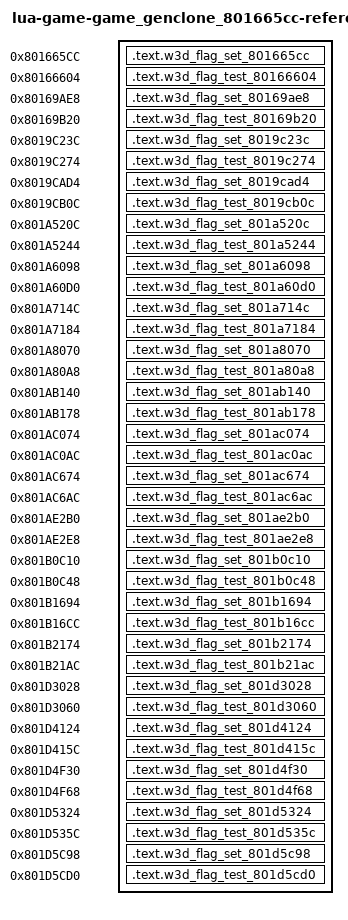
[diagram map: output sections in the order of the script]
/* Generated reference-only placements. All bodies are source-built. */
OUTPUT_FORMAT("elf32-powerpc")
OUTPUT_ARCH(powerpc)
ENTRY(w3d_flag_set_801665cc)
_SDA_BASE_ = 0x804b2540;
_SDA2_BASE_ = 0x804c2540;
SECTIONS {
  .text.w3d_flag_set_801665cc 0x801665cc : { *(.text.w3d_flag_set_801665cc) }
  .text.w3d_flag_test_80166604 0x80166604 : { *(.text.w3d_flag_test_80166604) }
  .text.w3d_flag_set_80169ae8 0x80169ae8 : { *(.text.w3d_flag_set_80169ae8) }
  .text.w3d_flag_test_80169b20 0x80169b20 : { *(.text.w3d_flag_test_80169b20) }
  .text.w3d_flag_set_8019c23c 0x8019c23c : { *(.text.w3d_flag_set_8019c23c) }
  .text.w3d_flag_test_8019c274 0x8019c274 : { *(.text.w3d_flag_test_8019c274) }
  .text.w3d_flag_set_8019cad4 0x8019cad4 : { *(.text.w3d_flag_set_8019cad4) }
  .text.w3d_flag_test_8019cb0c 0x8019cb0c : { *(.text.w3d_flag_test_8019cb0c) }
  .text.w3d_flag_set_801a520c 0x801a520c : { *(.text.w3d_flag_set_801a520c) }
  .text.w3d_flag_test_801a5244 0x801a5244 : { *(.text.w3d_flag_test_801a5244) }
  .text.w3d_flag_set_801a6098 0x801a6098 : { *(.text.w3d_flag_set_801a6098) }
  .text.w3d_flag_test_801a60d0 0x801a60d0 : { *(.text.w3d_flag_test_801a60d0) }
  .text.w3d_flag_set_801a714c 0x801a714c : { *(.text.w3d_flag_set_801a714c) }
  .text.w3d_flag_test_801a7184 0x801a7184 : { *(.text.w3d_flag_test_801a7184) }
  .text.w3d_flag_set_801a8070 0x801a8070 : { *(.text.w3d_flag_set_801a8070) }
  .text.w3d_flag_test_801a80a8 0x801a80a8 : { *(.text.w3d_flag_test_801a80a8) }
  .text.w3d_flag_set_801ab140 0x801ab140 : { *(.text.w3d_flag_set_801ab140) }
  .text.w3d_flag_test_801ab178 0x801ab178 : { *(.text.w3d_flag_test_801ab178) }
  .text.w3d_flag_set_801ac074 0x801ac074 : { *(.text.w3d_flag_set_801ac074) }
  .text.w3d_flag_test_801ac0ac 0x801ac0ac : { *(.text.w3d_flag_test_801ac0ac) }
  .text.w3d_flag_set_801ac674 0x801ac674 : { *(.text.w3d_flag_set_801ac674) }
  .text.w3d_flag_test_801ac6ac 0x801ac6ac : { *(.text.w3d_flag_test_801ac6ac) }
  .text.w3d_flag_set_801ae2b0 0x801ae2b0 : { *(.text.w3d_flag_set_801ae2b0) }
  .text.w3d_flag_test_801ae2e8 0x801ae2e8 : { *(.text.w3d_flag_test_801ae2e8) }
  .text.w3d_flag_set_801b0c10 0x801b0c10 : { *(.text.w3d_flag_set_801b0c10) }
  .text.w3d_flag_test_801b0c48 0x801b0c48 : { *(.text.w3d_flag_test_801b0c48) }
  .text.w3d_flag_set_801b1694 0x801b1694 : { *(.text.w3d_flag_set_801b1694) }
  .text.w3d_flag_test_801b16cc 0x801b16cc : { *(.text.w3d_flag_test_801b16cc) }
  .text.w3d_flag_set_801b2174 0x801b2174 : { *(.text.w3d_flag_set_801b2174) }
  .text.w3d_flag_test_801b21ac 0x801b21ac : { *(.text.w3d_flag_test_801b21ac) }
  .text.w3d_flag_set_801d3028 0x801d3028 : { *(.text.w3d_flag_set_801d3028) }
  .text.w3d_flag_test_801d3060 0x801d3060 : { *(.text.w3d_flag_test_801d3060) }
  .text.w3d_flag_set_801d4124 0x801d4124 : { *(.text.w3d_flag_set_801d4124) }
  .text.w3d_flag_test_801d415c 0x801d415c : { *(.text.w3d_flag_test_801d415c) }
  .text.w3d_flag_set_801d4f30 0x801d4f30 : { *(.text.w3d_flag_set_801d4f30) }
  .text.w3d_flag_test_801d4f68 0x801d4f68 : { *(.text.w3d_flag_test_801d4f68) }
  .text.w3d_flag_set_801d5324 0x801d5324 : { *(.text.w3d_flag_set_801d5324) }
  .text.w3d_flag_test_801d535c 0x801d535c : { *(.text.w3d_flag_test_801d535c) }
  .text.w3d_flag_set_801d5c98 0x801d5c98 : { *(.text.w3d_flag_set_801d5c98) }
  .text.w3d_flag_test_801d5cd0 0x801d5cd0 : { *(.text.w3d_flag_test_801d5cd0) }
  /DISCARD/ : { *(.text*) *(.rodata*) *(.data*) *(.bss*) *(.sdata*) *(.sbss*) *(.comment) }
}
